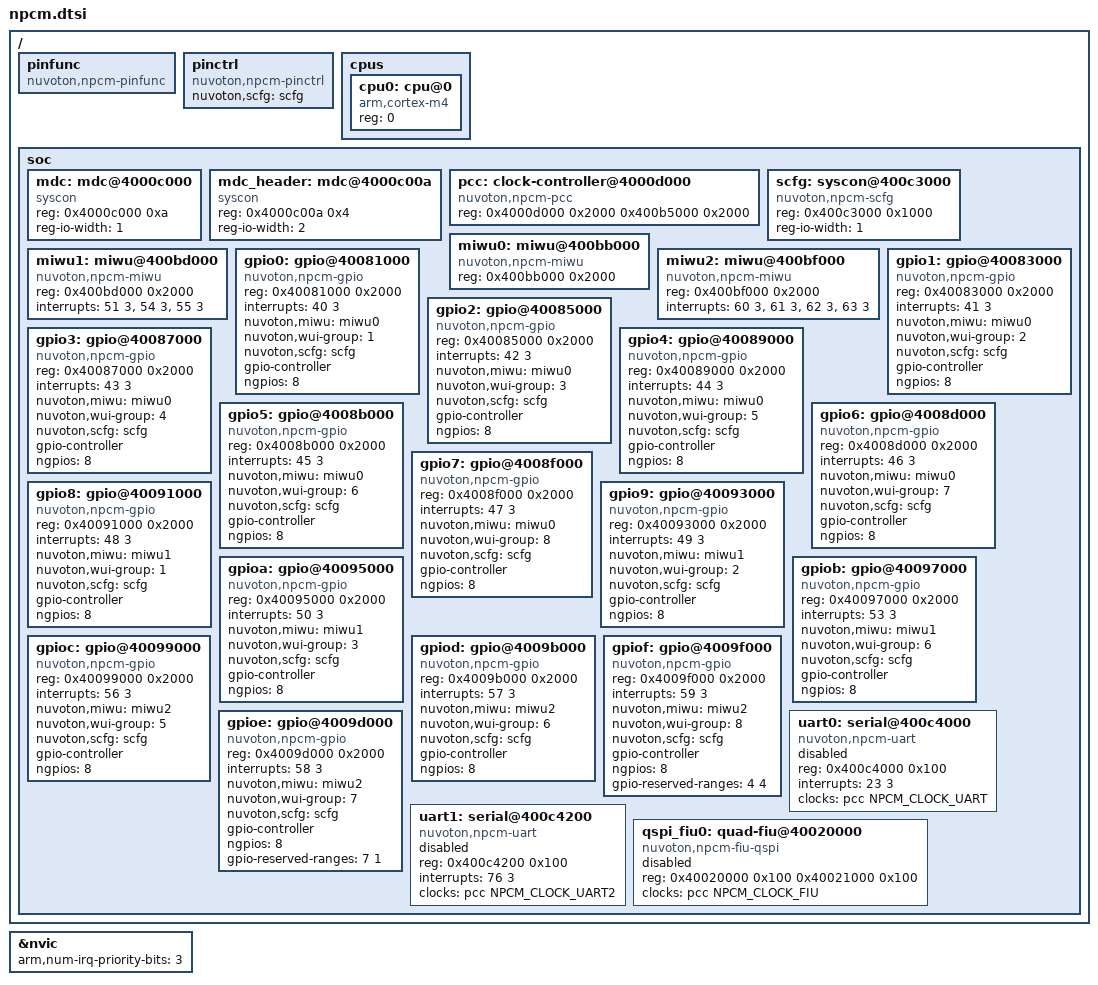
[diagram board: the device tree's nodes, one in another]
/*
 * Copyright (c) 2024 Nuvoton Technology Corporation.
 *
 * SPDX-License-Identifier: Apache-2.0
 */

#include <arm/armv7-m.dtsi>

/* Macros for device tree declarations of npcm soc family */
#include <zephyr/dt-bindings/clock/npcm_clock.h>
#include <freq.h>

/ {
	pinfunc: pinfunc {
		compatible = "nuvoton,npcm-pinfunc";
	};

	pinctrl: pinctrl {
		compatible = "nuvoton,npcm-pinctrl";
		nuvoton,scfg = <&scfg>;
	};

	cpus {
		#address-cells = <1>;
		#size-cells = <0>;

		cpu0: cpu@0 {
			device_type = "cpu";
			compatible = "arm,cortex-m4";
			reg = <0>;
		};
	};

	soc {
		mdc: mdc@4000c000 {
			compatible = "syscon";
			reg = <0x4000c000 0xa>;
			reg-io-width = <1>;
		};

		mdc_header: mdc@4000c00a {
			compatible = "syscon";
			reg = <0x4000c00a 0x4>;
			reg-io-width = <2>;
		};

		pcc: clock-controller@4000d000 {
			compatible = "nuvoton,npcm-pcc";
			/* Cells for clock id */
			#clock-cells = <1>;
			/* First reg region is Power Management Controller */
			/* Second reg region is Core Domain Clock Generator */
			reg = <0x4000d000 0x2000
			       0x400b5000 0x2000>;
			reg-names = "pmc", "cdcg";
		};

		scfg: syscon@400c3000 {
			compatible = "nuvoton,npcm-scfg", "syscon";
			/* System Configuration (SCFG) */
			reg = <0x400c3000 0x1000>;
			reg-io-width = <1>;
		};

		miwu0: miwu@400bb000 {
			compatible = "nuvoton,npcm-miwu";
			reg = <0x400bb000 0x2000>;
			#wui-cells = <2>;
		};

		miwu1: miwu@400bd000 {
			compatible = "nuvoton,npcm-miwu";
			reg = <0x400bd000 0x2000>;
			interrupts = <51 3>, <54 3>, <55 3>;
			interrupt-names = "wkintd", "wkintg", "wkinth";
			#wui-cells = <2>;
		};

		miwu2: miwu@400bf000 {
			compatible = "nuvoton,npcm-miwu";
			reg = <0x400bf000 0x2000>;
			interrupts = <60 3>, <61 3>, <62 3>, <63 3>;
			interrupt-names = "wkinta", "wkintb", "wkintc", "wkintd";
			#wui-cells = <2>;
		};

		gpio0: gpio@40081000 {
			compatible = "nuvoton,npcm-gpio";
			reg = <0x40081000 0x2000>;
			interrupts = <40 3>;
			nuvoton,miwu = <&miwu0>;
			nuvoton,wui-group = <1>;
			nuvoton,scfg = <&scfg>;
			gpio-controller;
			#gpio-cells = <2>;
			ngpios = <8>;
		};

		gpio1: gpio@40083000 {
			compatible = "nuvoton,npcm-gpio";
			reg = <0x40083000 0x2000>;
			interrupts = <41 3>;
			nuvoton,miwu = <&miwu0>;
			nuvoton,wui-group = <2>;
			nuvoton,scfg = <&scfg>;
			gpio-controller;
			#gpio-cells = <2>;
			ngpios = <8>;
		};

		gpio2: gpio@40085000 {
			compatible = "nuvoton,npcm-gpio";
			reg = <0x40085000 0x2000>;
			interrupts = <42 3>;
			nuvoton,miwu = <&miwu0>;
			nuvoton,wui-group = <3>;
			nuvoton,scfg = <&scfg>;
			gpio-controller;
			#gpio-cells = <2>;
			ngpios = <8>;
		};

		gpio3: gpio@40087000 {
			compatible = "nuvoton,npcm-gpio";
			reg = <0x40087000 0x2000>;
			interrupts = <43 3>;
			nuvoton,miwu = <&miwu0>;
			nuvoton,wui-group = <4>;
			nuvoton,scfg = <&scfg>;
			gpio-controller;
			#gpio-cells = <2>;
			ngpios = <8>;
		};

		gpio4: gpio@40089000 {
			compatible = "nuvoton,npcm-gpio";
			reg = <0x40089000 0x2000>;
			interrupts = <44 3>;
			nuvoton,miwu = <&miwu0>;
			nuvoton,wui-group = <5>;
			nuvoton,scfg = <&scfg>;
			gpio-controller;
			#gpio-cells = <2>;
			ngpios = <8>;
		};

		gpio5: gpio@4008b000 {
			compatible = "nuvoton,npcm-gpio";
			reg = <0x4008b000 0x2000>;
			interrupts = <45 3>;
			nuvoton,miwu = <&miwu0>;
			nuvoton,wui-group = <6>;
			nuvoton,scfg = <&scfg>;
			gpio-controller;
			#gpio-cells = <2>;
			ngpios = <8>;
		};

		gpio6: gpio@4008d000 {
			compatible = "nuvoton,npcm-gpio";
			reg = <0x4008d000 0x2000>;
			interrupts = <46 3>;
			nuvoton,miwu = <&miwu0>;
			nuvoton,wui-group = <7>;
			nuvoton,scfg = <&scfg>;
			gpio-controller;
			#gpio-cells = <2>;
			ngpios = <8>;
		};

		gpio7: gpio@4008f000 {
			compatible = "nuvoton,npcm-gpio";
			reg = <0x4008f000 0x2000>;
			interrupts = <47 3>;
			nuvoton,miwu = <&miwu0>;
			nuvoton,wui-group = <8>;
			nuvoton,scfg = <&scfg>;
			gpio-controller;
			#gpio-cells = <2>;
			ngpios = <8>;
		};

		gpio8: gpio@40091000 {
			compatible = "nuvoton,npcm-gpio";
			reg = <0x40091000 0x2000>;
			interrupts = <48 3>;
			nuvoton,miwu = <&miwu1>;
			nuvoton,wui-group = <1>;
			nuvoton,scfg = <&scfg>;
			gpio-controller;
			#gpio-cells = <2>;
			ngpios = <8>;
		};

		gpio9: gpio@40093000 {
			compatible = "nuvoton,npcm-gpio";
			reg = <0x40093000 0x2000>;
			interrupts = <49 3>;
			nuvoton,miwu = <&miwu1>;
			nuvoton,wui-group = <2>;
			nuvoton,scfg = <&scfg>;
			gpio-controller;
			#gpio-cells = <2>;
			ngpios = <8>;
		};

		gpioa: gpio@40095000 {
			compatible = "nuvoton,npcm-gpio";
			reg = <0x40095000 0x2000>;
			interrupts = <50 3>;
			nuvoton,miwu = <&miwu1>;
			nuvoton,wui-group = <3>;
			nuvoton,scfg = <&scfg>;
			gpio-controller;
			#gpio-cells = <2>;
			ngpios = <8>;
		};

		gpiob: gpio@40097000 {
			compatible = "nuvoton,npcm-gpio";
			reg = <0x40097000 0x2000>;
			interrupts = <53 3>;
			nuvoton,miwu = <&miwu1>;
			nuvoton,wui-group = <6>;
			nuvoton,scfg = <&scfg>;
			gpio-controller;
			#gpio-cells = <2>;
			ngpios = <8>;
		};

		gpioc: gpio@40099000 {
			compatible = "nuvoton,npcm-gpio";
			reg = <0x40099000 0x2000>;
			interrupts = <56 3>;
			nuvoton,miwu = <&miwu2>;
			nuvoton,wui-group = <5>;
			nuvoton,scfg = <&scfg>;
			gpio-controller;
			#gpio-cells = <2>;
			ngpios = <8>;
		};

		gpiod: gpio@4009b000 {
			compatible = "nuvoton,npcm-gpio";
			reg = <0x4009b000 0x2000>;
			interrupts = <57 3>;
			nuvoton,miwu = <&miwu2>;
			nuvoton,wui-group = <6>;
			nuvoton,scfg = <&scfg>;
			gpio-controller;
			#gpio-cells = <2>;
			ngpios = <8>;
		};

		gpioe: gpio@4009d000 {
			compatible = "nuvoton,npcm-gpio";
			reg = <0x4009d000 0x2000>;
			interrupts = <58 3>;
			nuvoton,miwu = <&miwu2>;
			nuvoton,wui-group = <7>;
			nuvoton,scfg = <&scfg>;
			gpio-controller;
			#gpio-cells = <2>;
			ngpios = <8>;
			gpio-reserved-ranges = <7 1>;
		};

		gpiof: gpio@4009f000 {
			compatible = "nuvoton,npcm-gpio";
			reg = <0x4009f000 0x2000>;
			interrupts = <59 3>;
			nuvoton,miwu = <&miwu2>;
			nuvoton,wui-group = <8>;
			nuvoton,scfg = <&scfg>;
			gpio-controller;
			#gpio-cells = <2>;
			ngpios = <8>;
			gpio-reserved-ranges = <4 4>;
		};

		uart0: serial@400c4000 {
			compatible = "nuvoton,npcm-uart";
			reg = <0x400c4000 0x100>;
			interrupts = <23 3>;
			clocks = <&pcc NPCM_CLOCK_UART>;
			status = "disabled";
		};

		uart1: serial@400c4200 {
			compatible = "nuvoton,npcm-uart";
			reg = <0x400c4200 0x100>;
			interrupts = <76 3>;
			clocks = <&pcc NPCM_CLOCK_UART2>;
			status = "disabled";
		};

		/*
		 * FIU0: Flash Interface Unit, shared/external SPI-NOR flash.
		 * Write-protect pinmux: NPCM400 has fiu0_wp_gpio55,
		 * fiu0_wp_gpio76 and fiu0_wp_int_fl; NPCM500 only has
		 * fiu0_wp_int_fl.
		 */
		qspi_fiu0: quad-fiu@40020000 {
			compatible = "nuvoton,npcm-fiu-qspi";
			#address-cells = <1>;
			#size-cells = <0>;
			reg = <0x40020000 0x100
			       0x40021000 0x100>;
			clocks = <&pcc NPCM_CLOCK_FIU>;
			status = "disabled";
		};
	};
};

&nvic {
	arm,num-irq-priority-bits = <3>;
};
